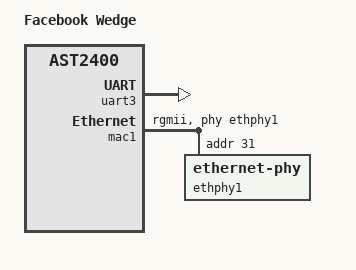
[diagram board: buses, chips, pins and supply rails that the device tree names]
/dts-v1/;

#include "ast2400-fboss.dtsi"

/ {
	model = "Facebook Wedge";
	compatible = "fbobmc,wedge40", "aspeed,ast2400";

	chosen {
		stdout-path = &uart3;
	};

	aliases {
		eth0 = &mac1;
	};
};

&uart3 {
	u-boot,dm-pre-reloc;
	status = "okay";
};

&mac1 {
	status = "okay";
	phy-mode = "rgmii";
	pinctrl-names = "default";
	pinctrl-0 = <&pinctrl_mac2link_default &pinctrl_mdio2_default>;
	phy-handle = <&ethphy1>;
	#address-cells = <1>;
	#size-cells = <0>;
	ethphy1: ethernet-phy@1 {
		reg = <31>;
	};
};
